# TLE984x register map
Vendor: Infineon Technologies AG; File version: 1.6
CPU: CM0 r0p0, little endian, no MPU, no FPU, 2 interrupt priority bits
Registers are 32-bit, read-write, no defined reset value unless marked. A register's access mark holds for its fields unless they carry their own. Offsets are from the block's base; [hi:lo] are bit positions; {n}, {i} and the like mark numbered series; 'fields as' and 'values as' point back to an identical list.

## GPT12E
Base 0x40010000
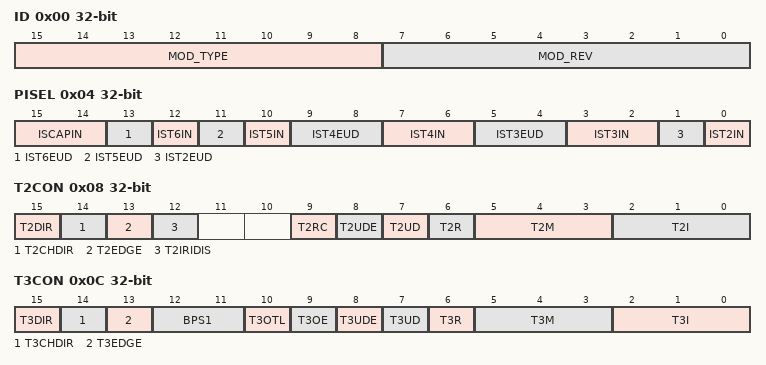
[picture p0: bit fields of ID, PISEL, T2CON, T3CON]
0x00 ID ro — Module Identification Register
  [15:8] MOD_TYPE — Module Identification Number
  [7:0] MOD_REV — Module Revision Number
0x04 PISEL — Port Input Select Register
  [15:14] ISCAPIN — Input Select for CAPIN
    0=CAPINA (Signal CAPINA is selected); 1=CAPINB (Signal CAPINB is selected); 2=CAPINC (Signal CAPINC (Read trigger from T3) is selected); 3=CAPIND (Signal CAPIND (Read trigger from T2 or T3 or T4) is selected)
  [13] IST6EUD — Input Select for T6EUD
    0=T6EUDA (Signal T6EUDA is selected); 1=T6EUDB (Signal T6EUDB is selected)
  [12] IST6IN — Input Select for T6IN
    0=T6INA (Signal T6INA is selected); 1=T6INB (Signal T6INB is selected)
  [11] IST5EUD — Input Select for T5EUD
    0=T5EUDA (Signal T5EUDA is selected); 1=T5EUDB (Signal T5EUDB is selected)
  [10] IST5IN — Input Select for T5IN
    0=T5INA (Signal T5INA is selected); 1=T5INB (Signal T5INB is selected)
  [9:8] IST4EUD — Input Select for TEUD
    0=T4EUDA (Signal T4EUDA is selected); 1=T4EUDB (Signal T4EUDB is selected); 2=T4EUDC (Signal T4EUDC is selected); 3=T4EUDD (Signal T4EUDD is selected)
  [7:6] IST4IN — Input Select for T4IN
    0=T4INA (Signal T4INA is selected); 1=T4INB (Signal T4INB is selected); 2=T4INC (Signal T4INC is selected); 3=T4IND (Signal T4IND is selected)
  [5:4] IST3EUD — Input Select for T3EUD
    0=T3EUDA (Signal T3EUDA is selected); 1=T3EUDB (Signal T3EUDB is selected); 2=T3EUDC (Signal T3EUDC is selected); 3=T3EUDD (Signal T3EUDD is selected)
  [3:2] IST3IN — Input Select for T3IN
    0=T3INA (Signal T3INA is selected); 1=T3INB (Signal T3INB is selected); 2=T3INC (Signal T3INC is selected); 3=T3IND (Signal T3IND is selected)
  [1] IST2EUD — Input Select for T2EUD
    0=T2EUDA (Signal T2EUDA is selected); 1=T2EUDB (Signal T2EUDB is selected)
  [0] IST2IN — Input Select for T2IN
    0=T2INA (Signal T2INA is selected); 1=T2INB (Signal T2INB is selected)
0x08 T2CON access per field — Timer T2 Control Register
  [15] T2DIR ro — Timer T2 Rotation Direction
    0=Up (Timer T2 counts up); 1=Down (Timer T2 counts down)
  [14] T2CHDIR rw — Timer T2 Count Direction Change
    0=No change of count direction was detected; 1=Change (A change of count direction was detected)
  [13] T2EDGE rw — Timer T2 Edge Detection
    0=No count edge was detected; 1=Count (A count edge was detected)
  [12] T2IRIDIS rw — Timer T2 Interrupt Disable
    0=Enabled (Interrupt generation for T2CHDIR and T2EDGE interrupts in Incremental Interface Mode is enabled); 1=Disabled (Interrupt generation for T2CHDIR and T2EDGE interrupts in Incremental Interface Mode is disabled)
  [9] T2RC rw — Timer T2 Remote Control
    0=T2R (Timer T2 is controlled by its own run bit T2R); 1=T3R (Timer T2 is controlled by the run bit T3R of core timer T3, not by bit T2R)
  [8] T2UDE rw — Timer T2 External Up/Down Enable
    0=T2UD (Count direction is controlled by bit T2UD; input T2EUD is disconnected); 1=T2EUD (Count direction is controlled by input T2EUD)
  [7] T2UD rw — Timer T2 Up/Down Control
    0=Up (Timer T2 counts up); 1=Down (Timer T2 counts down)
  [6] T2R rw — Timer T2 Input Run Bit
    0=Stop (Timer T2 stops); 1=Run (Timer T2 runs)
  [5:3] T2M rw — Timer T2 Input Mode Control
    0=Timer Mode; 1=Counter Mode; 2=Gated low (Gated Timer Mode with gate active low); 3=Gated high (Gated Timer Mode with gate active high); 4=Reload Mode; 5=Capture Mode; 6=Incremental Interface Mode - Rotation ((Rotation Detection Mode)); 7=Incremental Interface Mode - Edge ((Edge Detection Mode))
  [2:0] T2I rw — Timer T2 Input Parameter Selection
0x0C T3CON access per field — Timer T3 Control Register
  [15] T3DIR ro — Timer T3 Rotation Direction Flag
    0=Up (Timer T3 counts up); 1=Down (Timer T3 counts down)
  [14] T3CHDIR rw — Timer T3 Count Direction Change Flag
    values as T2CON.T2CHDIR
  [13] T3EDGE rw — Timer T3 Edge Detection Flag
    values as T2CON.T2EDGE
  [12:11] BPS1 rw — GPT1 Block Prescaler Control
    0=fGPT/8; 1=fGPT/4; 2=fGPT/32; 3=fGPT/16
  [10] T3OTL rw — Timer T3 Overflow Toggle Latch
  [9] T3OE rw — Overflow/Underflow Output Enable
    0=Disabled (Alternate Output Function Disabled); 1=T3OUT (State of T3 toggle latch is output on pin T3OUT)
  [8] T3UDE rw — Timer T3 External Up/Down Enable
    0=T3UD (Count direction is controlled by bit T3UD; input T3EUD is disconnected); 1=T3EUD (Count direction is controlled by input T3EUD)
  [7] T3UD rw — Timer T3 Up/Down Control
    0=Up (Timer T3 counts up); 1=Down (Timer T3 counts down)
  [6] T3R rw — Timer T3 Input Run Bit
    0=Stop (Timer T3 stops); 1=Run (Timer T3 runs)
  [5:3] T3M rw — Timer T3 Input Mode Control
    0=Timer Mode; 1=Counter Mode; 2=Gated low (Gated Timer Mode with gate active low); 3=Gated high (Gated Timer Mode with gate active high); 6=Incremental Interface Mode - Rotation ((Rotation Detection Mode)); 7=Incremental Interface Mode - Edge ((Edge Detection Mode))
  [2:0] T3I rw — Timer T3 Input Parameter Selection
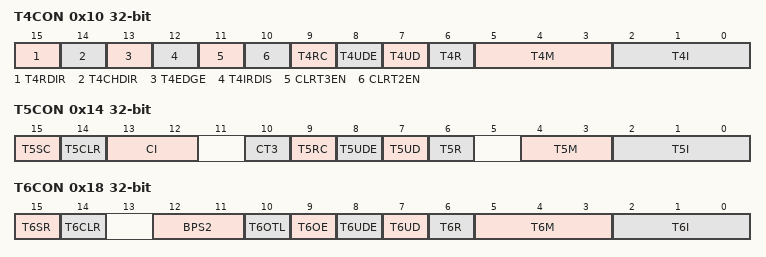
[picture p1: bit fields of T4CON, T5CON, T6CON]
0x10 T4CON access per field — Timer T4 Control Register
  [15] T4RDIR ro — Timer T4 Rotation Direction
    0=Up (Timer T4 counts up); 1=Down (Timer T4 counts down)
  [14] T4CHDIR rw — Timer T4 Count Direction Change
    0=No change in count direction was detected; 1=Change (A change in count direction was detected)
  [13] T4EDGE rw — Timer T4 Edge Direction
    values as T2CON.T2EDGE
  [12] T4IRDIS rw — Timer T4 Interrupt Disable
    0=Enabled (Interrupt generation for T4CHDIR and T4EDGE interrupts in Incremental Interface Mode is enabled); 1=Disabled (Interrupt generation for T4CHDIR and T4EDGE interrupts in Incremental Interface Mode is disabled)
  [11] CLRT3EN rw — Clear Timer T3 Enable
    0=No effect of T4IN on Timer T3; 1=Clear (A falling edge on T4In clears timer T3)
  [10] CLRT2EN rw — Clear Timer T2 Enable
    0=No effect of T4EUD on timer T2; 1=Clear (A falling edge on T4EUD clears timer T2)
  [9] T4RC rw — Timer T4 Remote Control
    0=T4R (Timer T4 is controlled by its own run bit T4R); 1=T3R (Timer T4 is controlled by the run bit T3R of core timer T3, but not by bit T4R)
  [8] T4UDE rw — Timer T4 External Up/Down Enable
    0=T4UD (Count direction is controlled by bit T4UD; input T4EUD is disconnected); 1=T4EUD (Count direction is controlled by input T4EUD)
  [7] T4UD rw — Timer T2 Up/Down Control
    0=Up (Timer T2 counts up); 1=Down (Timer T2 counts down)
  [6] T4R rw — Timer T4 Input Run Bit
    0=Stop (Timer T4 stops); 1=Run (Timer T4 runs)
  [5:3] T4M rw — Timer T4 Mode Control (Basic Operating Mode)
    values as T2CON.T2M
  [2:0] T4I rw — Timer T4 Input Parameter Selection
0x14 T5CON — Timer T5 Control Register
  [15] T5SC — Timer T5 Capture Mode Enable
    0=Disabled (Capture into register CAPREL disabled); 1=Enabled (Capture into register CAPREL enabled)
  [14] T5CLR — Timer T5 Clear Enable Bit
    0=Not cleared (Timer T5 is not cleared on a capture event); 1=Cleared (Timer T5 is cleared on a capture event)
  [13:12] CI — Register CAPREL Capture Trigger Selection
    0=Disabled (Capture disabled); 1=Positive transition (rising edge) on CAPIN or any transition on T3IN; 2=Negative transition (falling edge) on CAPIN or any transition on T3EUD; 3=Any (Any transition (rising or falling edge) on CAPIN or any transition on T3IN or T3EUD)
  [10] CT3 — Timer T3 Capture Trigger Enable
    0=CAPIN (Capture trigger from input line CAPIN); 1=T3IN (Capture trigger from T3 input lines T3IN and/or T3EUD)
  [9] T5RC — Timer T5 Remote Control
    0=T5R (Timer T5 is controlled by its own run bit T5R); 1=T6R (Timer T5 is controlled by the run bit T6R of core timer T6, not by bit T5R)
  [8] T5UDE — Timer T5 External Up/Down Enable
    0=T5UD (Count direction is controlled by bit T5UD; input T5EUD is disconnected); 1=T5EUD (Count direction is controlled by input T5EUD)
  [7] T5UD — Timer T2 Up/Down Control
    0=Up (Timer T5 counts up); 1=Down (Timer T5 counts down)
  [6] T5R — Timer T5 Run Bit
    0=Stop (Timer T5 stops); 1=Run (Timer T5 runs)
  [4:3] T5M — Timer T5 Input Mode Control
    0=Timer Mode; 1=Counter Mode; 2=Gated low (Gated Timer Mode with gate active low); 3=Gated high (Gated Timer Mode with gate active high)
  [2:0] T5I — Timer T5 Input Parameter Selection
0x18 T6CON — Timer T6 Control Register
  [15] T6SR — Timer T6 Reload Mode Enable
    0=Disabled (Reload from register CAPREL disabled); 1=Enabled (Reload from register CAPREL enabled)
  [14] T6CLR — Timer T6 Clear Enable Bit
    0=Not cleared (Timer T6 is not cleared on a capture event); 1=Cleared (Timer T6 is cleared on a capture event)
  [12:11] BPS2 — GPT2 Block Prescaler Control
    0=fGPT/4; 1=fGPT/2; 2=fGPT/16; 3=fGPT/8
  [10] T6OTL — Timer T6 Overflow Toggle Latch
  [9] T6OE — Overflow/Underflow Output Enable
    0=Disabled (Alternate Output Function Disabled); 1=T6OUT (State of T6 toggle latch is output on pin T6OUT)
  [8] T6UDE — Timer T6 External Up/Down Enable
    0=T6UD (Count direction is controlled by bit T6UD; input T6EUD is disconnected); 1=T6EUD (Count direction is controlled by input T6EUD)
  [7] T6UD — Timer T6 Up/Down Control
    0=Up (Timer T3 counts up); 1=Down (Timer T3 counts down)
  [6] T6R — Timer T6 Input Run Bit
    0=Stop (Timer T3 stops); 1=Run (Timer T3 runs)
  [5:3] T6M — Timer T6 Mode Control
    values as T5CON.T5M
  [2:0] T6I — Timer T6 Input Parameter Selection
0x1C CAPREL — Capture/Reload Register
  [15:0] CAPREL — Current reload value or Captured value
{0x18+4i} T{i} (i=2..4) — Timer T{i} Count Register
  [15:0] T{i} — Timer T{i} Current Value
0x2C T5 — Timer 5 Count Register
  [15:0] T5 — Timer T5 Current Value
0x30 T6 — Timer 6 Count Register
  [15:0] T6 — Timer T6 Current Value
